# S32K312_M7 register map
Vendor: NXP Semiconductors; File version: 1.3
CPU: CM7 r0p1, little endian, MPU, FPU, VTOR, 4 interrupt priority bits
Registers are 32-bit, read-write, reset 0x0 unless marked. A register's access mark holds for its fields unless they carry their own. Offsets are from the block's base; [hi:lo] are bit positions; {n}, {i} and the like mark numbered series; 'fields as' and 'values as' point back to an identical list.

## MC_CGM
Base 0x402D8000
0x00 PCFS_SDUR — PCFS Step Duration
  [15:0] SDUR — Step duration
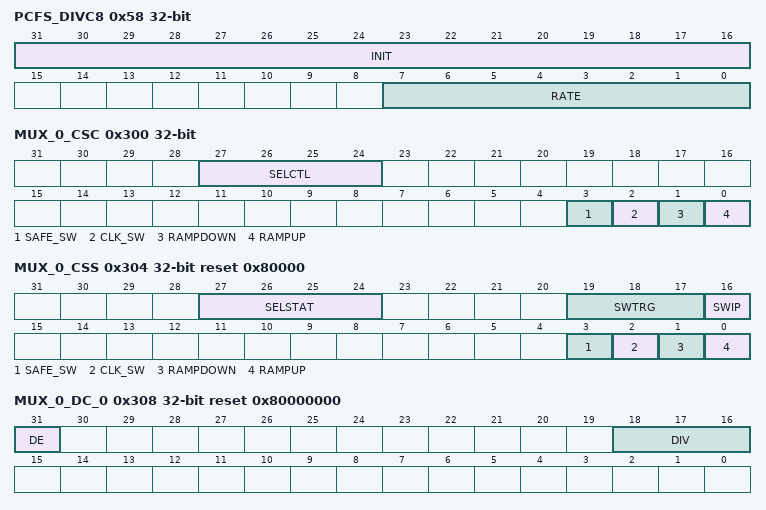
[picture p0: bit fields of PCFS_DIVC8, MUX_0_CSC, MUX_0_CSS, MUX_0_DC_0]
0x58 PCFS_DIVC8 — PCFS Divider Change 8 Register
  [31:16] INIT — Divider change initial value
  [7:0] RATE — Divider change rate
0x5C PCFS_DIVE8 reset 0x3E7 — PCFS Divider End 8 Register
  [19:0] DIVE — Divider end value
0x60 PCFS_DIVS8 reset 0x3E7 — PCFS Divider Start 8 Register
  [19:0] DIVS — Divider start value
0x300 MUX_0_CSC — Clock Mux 0 Select Control Register
  [27:24] SELCTL — Clock source selection control
    0=clk_src_0 (FIRC); 8=clk_src_8 (PLL_PHI0_CLK)
  [3] SAFE_SW — Safe clock request
  [2] CLK_SW — Clock switch
  [1] RAMPDOWN — PCFS ramp-down
  [0] RAMPUP — PCFS ramp-up
0x304 MUX_0_CSS ro reset 0x80000 — Clock Mux 0 Select Status Register
  [27:24] SELSTAT — Clock source selection status
    0=clk_src_0 (FIRC); 8=clk_src_8 (PLL_PHI0_CLK)
  [19:17] SWTRG — Switch trigger cause
    1=SUCCESS (Switch after request succeeded.); 2=FAIL_TARGET_CLOCK (Switch after the request failed because of an inactive target clock and the current clock is FIRC.); 3=FAIL_CURRENT_CLOCK (Switch after the request failed because of an inactive current clock and the current clock is FIRC.); 4=REQ_SUCCEED (Switch to FIRC because of a safe clock request or reset succeeded.); 5=REQ_SUCCEED_INACTIVE (Switch to FIRC because of a safe clock request or reset succeeded, but the previous current clock source was inactive.)
  [16] SWIP — Switch in progress
    0=COMPETE (Clock source switching is complete.); 1=IN_PROGRESS (Clock source switching is in progress.)
  [3] SAFE_SW — Safe clock request
    0=NO_CLOCK (No safe clock switch operation was requested.); 1=CLOCK (Safe clock switch operation was requested.)
  [2] CLK_SW — Clock switch
    0=NO_CLOCK (No clock switch operation was requested.); 1=CLOCK (Clock switch operation was requested.)
  [1] RAMPDOWN — PCFS ramp-down
    0=NO_RAMPUP (No ramp-down operation was requested.); 1=RAMPUP (Ramp-down operation was requested.)
  [0] RAMPUP — PCFS ramp-up
    0=NO_RAMP_UP (No ramp-up operation was requested.); 1=RAMP_UP (Ramp-up operation was requested.)
0x308 MUX_0_DC_0 reset 0x80000000 — Clock Mux 0 Divider 0 Control Register
  [31] DE ro — Divider enable
    0=DISABLED (Reserved); 1=ENABLED (Divider is enabled.)
  [18:16] DIV — Division value
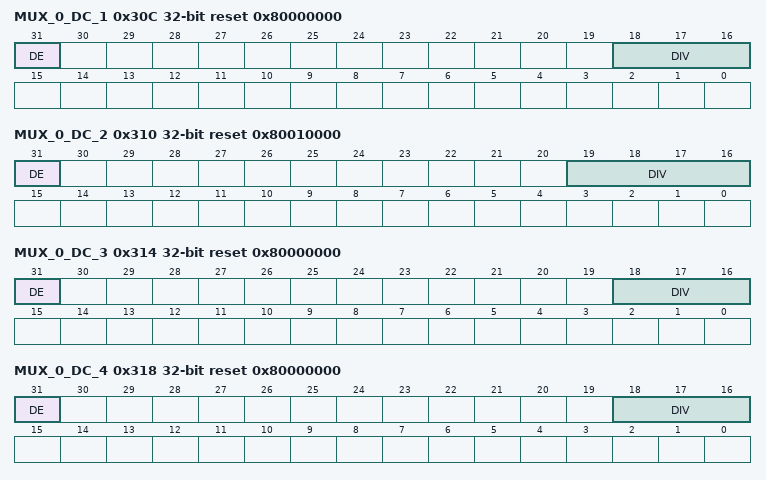
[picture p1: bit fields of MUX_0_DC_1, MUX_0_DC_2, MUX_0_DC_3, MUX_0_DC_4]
0x30C MUX_0_DC_1 reset 0x80000000 — Clock Mux 0 Divider 1 Control Register
  fields as MUX_0_DC_0
0x310 MUX_0_DC_2 reset 0x80010000 — Clock Mux 0 Divider 2 Control Register
  [31] DE ro — Divider enable
    0=DISABLED (Reserved); 1=ENABLED (Divider is enabled.)
  [19:16] DIV — Division value
0x314 MUX_0_DC_3 reset 0x80000000 — Clock Mux 0 Divider 3 Control Register
  fields as MUX_0_DC_0
0x318 MUX_0_DC_4 reset 0x80000000 — Clock Mux 0 Divider 4 Control Register
  fields as MUX_0_DC_0
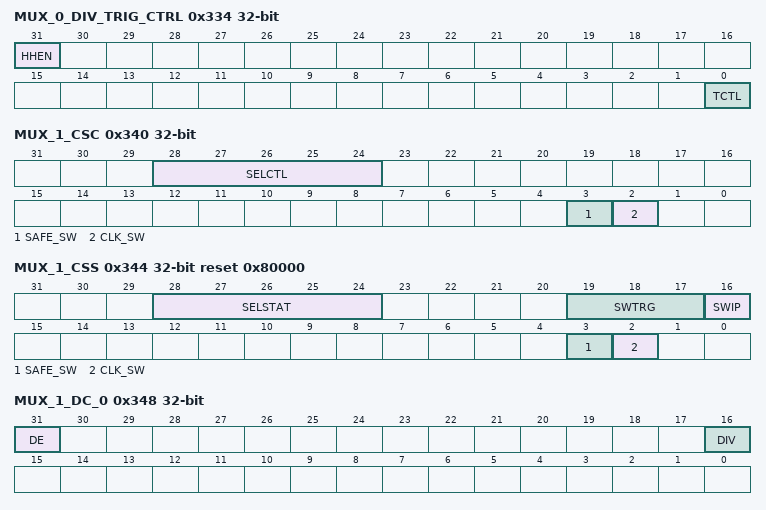
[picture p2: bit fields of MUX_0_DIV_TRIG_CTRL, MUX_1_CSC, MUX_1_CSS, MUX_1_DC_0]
0x334 MUX_0_DIV_TRIG_CTRL — Clock Mux 0 Divider Trigger Control Register
  [31] HHEN — Halt handshake enable
    0=NO_HALT (No halt handshake protocol is initiated.); 1=HALT (Halt handshake protocol is initiated.)
  [0] TCTL — Trigger control
    0=IMMEDIATE (Immediate divider update); 1=COMMON (Common trigger divider update)
0x338 MUX_0_DIV_TRIG — Clock Mux 0 Divider Trigger Register
  [31:0] TRIGGER — Trigger for divider update
0x33C MUX_0_DIV_UPD_STAT ro — Clock Mux 0 Divider Update Status Register
  [0] DIV_STAT — Divider status for clock mux 0
    0=NO_DIV_PENDING (No divider configuration update is pending.); 1=DIV_PENDING (Divider configuration update on at least one divider associated with this multiplexer is pending.)
0x340 MUX_1_CSC — Clock Mux 1 Select Control Register
  [28:24] SELCTL — Clock source selection control
    0=clk_src_0 (FIRC); 2=clk_src_2 (FXOSC); 22=clk_src_22 (AIPS_PLAT_CLK)
  [3] SAFE_SW — Safe clock request
  [2] CLK_SW — Clock switch
0x344 MUX_1_CSS ro reset 0x80000 — Clock Mux 1 Select Status Register
  [28:24] SELSTAT — Clock source selection status
    values as MUX_1_CSC.SELCTL
  [19:17] SWTRG — Switch trigger cause
    values as MUX_0_CSS.SWTRG
  [16] SWIP — Switch in progress
    values as MUX_0_CSS.SWIP
  [3] SAFE_SW — Safe clock request
    values as MUX_0_CSS.SAFE_SW
  [2] CLK_SW — Clock switch
    values as MUX_0_CSS.CLK_SW
0x348 MUX_1_DC_0 — Clock Mux 1 Divider 0 Control Register
  [31] DE — Divider enable
    0=DISABLED (Divider is disabled.); 1=ENABLED (Divider is enabled.)
  [16] DIV — Division value
0x37C MUX_1_DIV_UPD_STAT ro — Clock Mux 1 Divider Update Status Register
  [0] DIV_STAT — Divider status for clock mux 1
    values as MUX_0_DIV_UPD_STAT.DIV_STAT
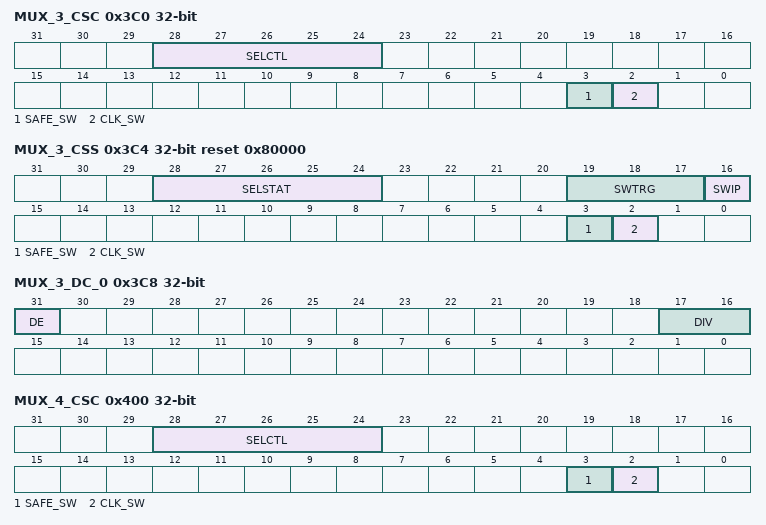
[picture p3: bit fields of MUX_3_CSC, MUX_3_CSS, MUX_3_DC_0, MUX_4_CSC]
0x3C0 MUX_3_CSC — Clock Mux 3 Select Control Register
  fields as MUX_1_CSC
0x3C4 MUX_3_CSS ro reset 0x80000 — Clock Mux 3 Select Status Register
  fields as MUX_1_CSS
0x3C8 MUX_3_DC_0 — Clock Mux 3 Divider 0 Control Register
  [31] DE — Divider enable
    values as MUX_1_DC_0.DE
  [17:16] DIV — Division value
{0x33C+0x40*i} MUX_{i}_DIV_UPD_STAT ro (i=3..6) — Clock Mux {i} Divider Update Status Register
  [0] DIV_STAT — Divider status for clock mux {i}
    values as MUX_0_DIV_UPD_STAT.DIV_STAT
0x400 MUX_4_CSC — Clock Mux 4 Select Control Register
  fields as MUX_1_CSC
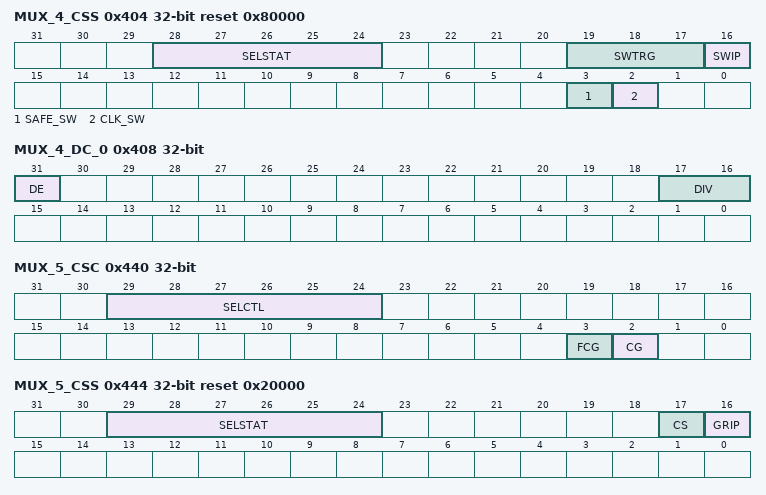
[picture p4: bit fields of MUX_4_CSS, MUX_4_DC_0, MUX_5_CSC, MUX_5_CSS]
0x404 MUX_4_CSS ro reset 0x80000 — Clock Mux 4 Select Status Register
  fields as MUX_1_CSS
0x408 MUX_4_DC_0 — Clock Mux 4 Divider 0 Control Register
  fields as MUX_3_DC_0
0x440 MUX_5_CSC — Clock Mux 5 Select Control Register
  [29:24] SELCTL — Clock source selection control
    0=clk_src_0 (FIRC); 1=clk_src_1 (SIRC); 2=clk_src_2 (FXOSC); 4=clk_src_4 (SXOSC); 23=clk_src_23 (AIPS_SLOW_CLK)
  [3] FCG — Force clock gate
  [2] CG — Clock gate
0x444 MUX_5_CSS ro reset 0x20000 — Clock Mux 5 Select Status Register
  [29:24] SELSTAT — Clock source selection status
    values as MUX_5_CSC.SELCTL
  [17] CS — Clock status
    0=GATED (Clock is gated to logic-0 at output of clock mux); 1=TRANSPARENTs (Clock mux is transparent. Active clock pulses at input of clock mux results in same number of pulses at its output)
  [16] GRIP — Gating request is in progress.
    0=COMPLETED (Clock source gating or ungating has completed.); 1=IN_PROGRESS (Clock source gating or ungating is in progress.)
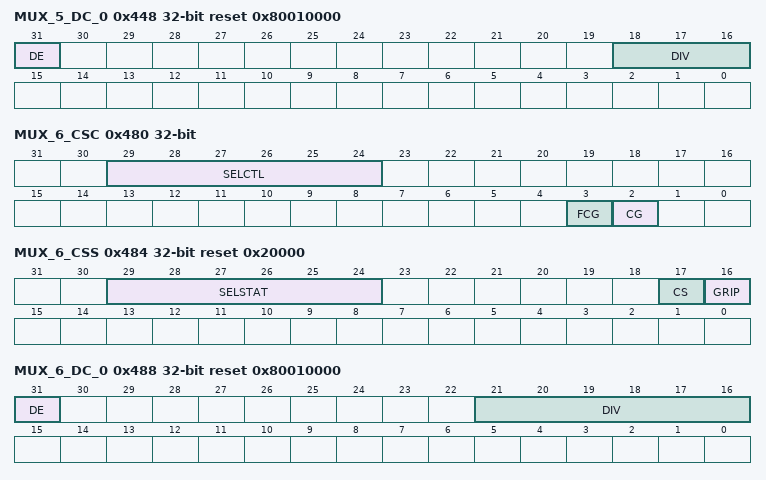
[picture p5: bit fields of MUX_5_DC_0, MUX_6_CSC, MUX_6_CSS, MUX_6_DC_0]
0x448 MUX_5_DC_0 reset 0x80010000 — Clock Mux 5 Divider 0 Control Register
  [31] DE — Divider enable
    values as MUX_1_DC_0.DE
  [18:16] DIV — Division value
0x480 MUX_6_CSC — Clock Mux 6 Select Control Register
  [29:24] SELCTL — Clock source selection control
    0=clk_src_0 (FIRC); 1=clk_src_1 (SIRC); 2=clk_src_2 (FXOSC); 4=clk_src_4 (SXOSC); 8=clk_src_8 (PLL_PHI0_CLK); 9=clk_src_9 (PLL_PHI1_CLK); 16=clk_src_16 (CORE_CLK); 19=clk_src_19 (HSE_CLK); 22=clk_src_22 (AIPS_PLAT_CLK); 23=clk_src_23 (AIPS_SLOW_CLK)
  [3] FCG — Force clock gate
  [2] CG — Clock gate
0x484 MUX_6_CSS ro reset 0x20000 — Clock Mux 6 Select Status Register
  [29:24] SELSTAT — Clock source selection status
    values as MUX_6_CSC.SELCTL
  [17] CS — Clock status
    values as MUX_5_CSS.CS
  [16] GRIP — Gating request is in progress.
    values as MUX_5_CSS.GRIP
0x488 MUX_6_DC_0 reset 0x80010000 — Clock Mux 6 Divider 0 Control Register
  [31] DE — Divider enable
    values as MUX_1_DC_0.DE
  [21:16] DIV — Division value
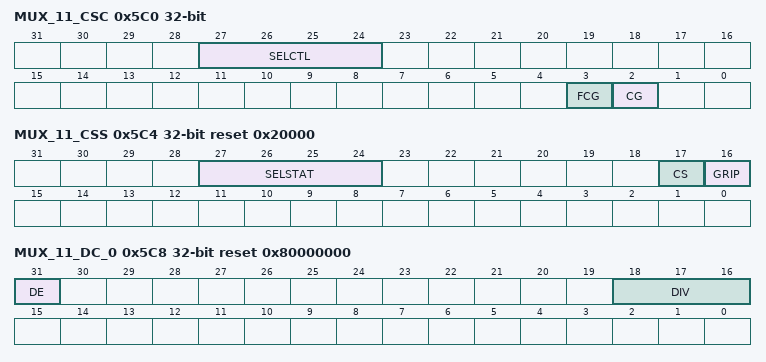
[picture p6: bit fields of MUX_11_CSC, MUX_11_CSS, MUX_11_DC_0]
0x5C0 MUX_11_CSC — Clock Mux 11 Select Control Register
  [27:24] SELCTL — Clock source selection control
    0=clk_src_0 (FIRC); 2=clk_src_2 (FXOSC); 8=clk_src_8 (PLL_PHI0_CLK); 9=clk_src_9 (PLL_PHI1_CLK)
  [3] FCG — Force clock gate
  [2] CG — Clock gate
0x5C4 MUX_11_CSS ro reset 0x20000 — Clock Mux 11 Select Status Register
  [27:24] SELSTAT — Clock source selection status
    values as MUX_11_CSC.SELCTL
  [17] CS — Clock status
    values as MUX_5_CSS.CS
  [16] GRIP — Gating request is in progress.
    values as MUX_5_CSS.GRIP
0x5C8 MUX_11_DC_0 reset 0x80000000 — Clock Mux 11 Divider 0 Control Register
  fields as MUX_5_DC_0
0x5FC MUX_11_DIV_UPD_STAT ro — Clock Mux 11 Divider Update Status Register
  [0] DIV_STAT — Divider status for clock mux 11
    values as MUX_0_DIV_UPD_STAT.DIV_STAT
